# APM32F445 register map
File version: 1.0
CPU: CM4 r0p1, little endian, MPU, FPU, 4 interrupt priority bits
Registers are 32-bit, read-write, reset 0x0 unless marked. A register's access mark holds for its fields unless they carry their own. Offsets are from the block's base; [hi:lo] are bit positions; 'fields as' and 'values as' point back to an identical list.

## MC — Core Platform Miscellaneous Control Module
Base 0xE0080000
0x08 SINCSTS 16-bit ro reset 0x7 — XBARSW Slave Input Port Connection Status
  [7:0] SINCFLG — XBARSW Slave Input Port Connection Flag
    0=A bus slave connection to AXBS input port n is absent; 1=A bus slave connection to AXBS input port n is present
0x0A MINCSTS 16-bit ro reset 0x7 — XBARSW Master Input Port Connection Status
  [7:0] MINCFLG — XBARSW Master Input Port Connection Flag
    0=A bus master connection to AXBS input port n is absent; 1=A bus master connection to AXBS input port n is present
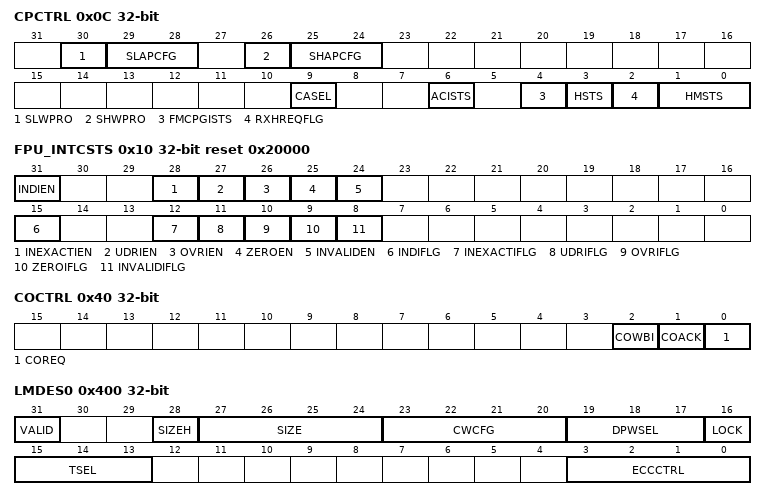
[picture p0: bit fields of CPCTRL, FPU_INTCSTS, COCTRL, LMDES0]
0x0C CPCTRL (reset mask 0xFFFFFFAF) — Core Platform Control Register
  [30] SLWPRO — SRAM_L Write Protect
  [29:28] SLAPCFG — SRAM_L Arbitration Priority Configure
    0=Round robin; 1=Special round robin (favors SRAM backdoor accesses over the processor); 2=Fixed priority. Processor has highest, backdoor has lowest; 3=Fixed priority. Backdoor has highest, processor has lowest
  [26] SHWPRO — SRAM_H Write Protect
  [25:24] SHAPCFG — SRAM_H Arbitration Priority Configure
    values as SLAPCFG
  [9] CASEL — Crossbar Arbitration Select
    0=Fixed-priority arbitration; 1=Round-robin arbitration
  [6] ACISTS ro — AC Idle Status
    0=PBRIDGE is not idle; 1=PBRIDGE is currently idle
  [4] FMCPGISTS ro — Flash Memory Controller Program Idle Status
    0=FMC program flash is not idle; 1=FMC program flash is currently idle
  [3] HSTS ro — XBARSW Halt Status
    0=AXBS is not currently halted; 1=AXBS is currently halted
  [2] RXHREQFLG ro — XBARSW Receive Halt Request Flag
    0=AXBS is not receiving halt request; 1=AXBS is receiving halt request
  [1:0] HMSTS ro — XBARSW Halt Machine Status
    0=Waiting for request; 1=Waiting for platform idle; 3=Platform stalled; 2=Unused state
0x10 FPU_INTCSTS reset 0x20000 — FPU Interrupt Control and Status Register
  [31] INDIEN — FPU Input Denormal Enable
    0=Disable interrupt; 1=Enable interrupt
  [28] INEXACTIEN — FPU Inexact Enable
    0=Disable interrupt; 1=Enable interrupt
  [27] UDRIEN — FPU Underflow Enable
    0=Disable interrupt; 1=Enable interrupt
  [26] OVRIEN — FPU Overflow Enable
    0=Disable interrupt; 1=Enable interrupt
  [25] ZEROEN — FPU Divide-by-Zero Enable
    0=Disable interrupt; 1=Enable interrupt
  [24] INVALIDEN — FPU Invalid Operation Enable
    0=Disable interrupt; 1=Enable interrupt
  [15] INDIFLG ro — FPU Input Denormal Interrupt Flag
    0=No interrupt; 1=Interrupt occurred
  [12] INEXACTIFLG ro — FPU Inexact Interrupt Flag
    0=No interrupt; 1=Interrupt occurred
  [11] UDRIFLG ro — FPU Underflow Interrupt Flag
    0=No interrupt; 1=Interrupt occurred
  [10] OVRIFLG ro — FPU Overflow Interrupt Flag
    0=No interrupt; 1=Interrupt occurred
  [9] ZEROIFLG ro — FPU Divide-by-Zero Interrupt Flag
    0=No interrupt; 1=Interrupt occurred
  [8] INVALIDIFLG ro — FPU Invalid Operation Interrupt Flag
    0=No interrupt; 1=Interrupt occurred
0x30 PID — Process ID Register
  [7:0] PID — M0_PID and M1_PID Values in the MPU Drive
0x40 COCTRL — Compute Operation Control Register
  [2] COWBI — Compute Operation Wakeup By Interrupt
    0=No effect; 1=When set, the CPOREQ is cleared on any interrupt or exception vector fetch
  [1] COACK ro — Compute Operation Acknowledge
    0=Compute operation entry has not completed or compute operation exit has completed; 1=Compute operation entry has completed or compute operation exit has not completed
  [0] COREQ — Compute Operation Request
    0=Request is cleared; 1=Request Compute Operation
0x400 LMDES0 reset not defined — Local Memory Descriptor Register0
  [31] VALID ro — Local Memory Valid
    0=LMCn is not present; 1=LMCn is present
  [28] SIZEH ro — LMC Size Hole
    0=LMCn is a power-of-2 capacity; 1=LMCn is not a power-of-2, with a capacity is 0.75 * LMSZ
  [27:24] SIZE ro — LMC Size
    0=no LMCn (0 KB); 1=1 KB LMCn; 2=2 KB LMCn; 3=4 KB LMCn; 4=8 KB LMCn; 5=16 KB LMCn; 6=32 KB LMCn; 7=64 KB LMCn; 8=128 KB LMCn; 9=256 KB LMCn; 10=512 KB LMCn; 11=1024 KB LMCn; 12=2048 KB LMCn; 13=4096 KB LMCn; 14=8192 KB LMCn; 15=16384 KB LMCn
  [23:20] CWCFG ro — Level 1 Cache Ways Configure
    0=No Cache; 2=2-Way Set Associative; 4=4-Way Set Associative
  [19:17] DPWSEL ro — LMC Data Path Width Select
    2=LMCn 32-bits wide; 3=LMCn 64-bits wide
  [16] LOCK
    0=Writes to the LMDRn[7:0] are allowed; 1=Writes to the LMDRn[7:0] are ignored
  [15:13] TSEL ro — Local Memory Type Select
    0=SRAM_L; 1=SRAM_U
  [3:0] ECCCTRL — TCM ECC Control
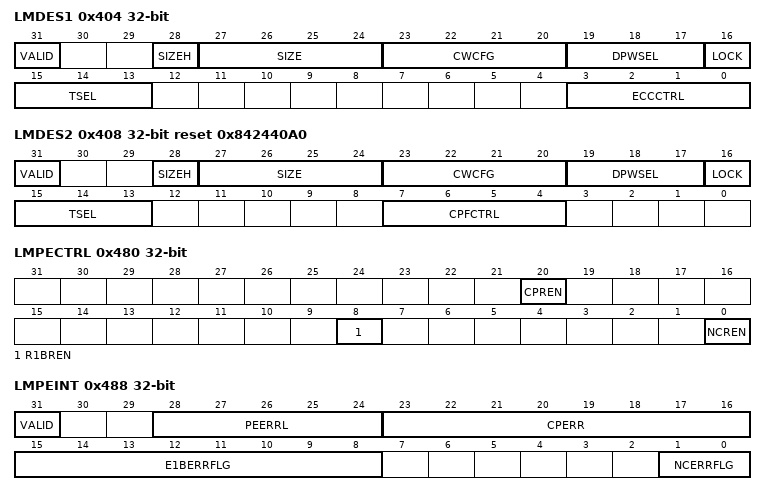
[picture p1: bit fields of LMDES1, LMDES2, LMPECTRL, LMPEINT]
0x404 LMDES1 reset not defined — Local Memory Descriptor Register1
  fields as LMDES0
0x408 LMDES2 reset 0x842440A0 — Local Memory Descriptor Register2
  [31] VALID ro — Local Memory Valid
    0=LMCn is not present; 1=LMCn is present
  [28] SIZEH ro — LMC Size Hole
    values as LMDES0.SIZEH
  [27:24] SIZE ro — LMC Size
    4=4 KB LMCn
  [23:20] CWCFG ro — Level 1 Cache Ways Configure
    0=No Cache; 2=2-Way Set Associative; 4=4-Way Set Associative
  [19:17] DPWSEL ro — LMC Data Path Width Select
    2=LMCn 32-bits wide; 3=LMCn 64-bits wide
  [16] LOCK
    values as LMDES0.LOCK
  [15:13] TSEL ro — Local Memory Type Select
    2=PC Cache
  [7:4] CPFCTRL — Cache Parity Functions Control
0x480 LMPECTRL — LMC Parity and ECC Control Register
  [all] fields
    0=Reporting disabled; 1=Reporting enabled
  [20] CPREN — Cache Parity Reporting Enable
  [8] R1BREN — RAM ECC 1 Bit Reporting Enable
  [0] NCREN — RAM ECC Noncorrectable Reporting Enable
0x488 LMPEINT — LMC Parity and ECC Interrupt Register
  [31] VALID ro
  [28:24] PEERRL ro — Parity or ECC Error Location
    0=Non-correctable ECC event from SRAM_L; 1=Non-correctable ECC event from SRAM_U
  [23:16] CPERR — Cache Parity Error
  [15:8] E1BERRFLG — ECC 1-bit Error Flag
  [1:0] NCERRFLG — ECC Noncorrectable Error Flag
0x490 LMFADDR ro — LMC Fault Address Register
  [31:0] EFADDR — ECC Fault Address
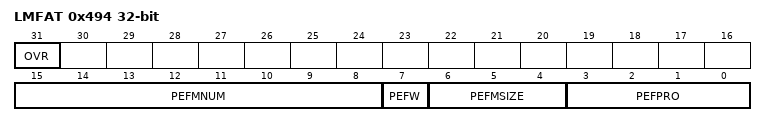
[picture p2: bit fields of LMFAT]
0x494 LMFAT ro — LMC Fault Attribute Register
  [31] OVR — Overrun
  [15:8] PEFMNUM — Parity/ECC Fault Master Number
  [7] PEFW — Parity/ECC Fault Write
  [6:4] PEFMSIZE — Parity/ECC Fault Master Size
    0=8-bit access; 1=16-bit access; 2=32-bit access; 3=64-bit access
  [3:0] PEFPRO — Parity/ECC Fault Protection
0x4A0 LMFDATAH ro — LMC Fault Data High Register
  [31:0] PEFH — Parity/ ECC Fault Data High
0x4A4 LMFDATAL ro — LMC Fault Data Low Register
  [31:0] PEFL — Parity/ ECC Fault Data Low
